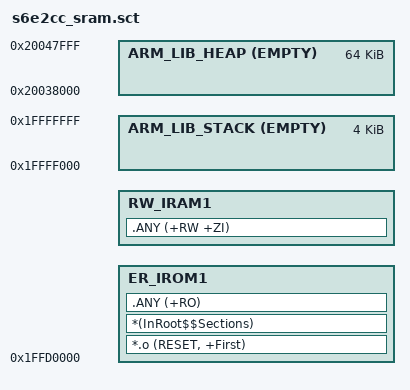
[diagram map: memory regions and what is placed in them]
;****************************************************************
;* S6E2CC linker scatter file (running code from internal SRAM) *
;****************************************************************

LR_IROM1 0x1FFD0000 0x30000
{
   ER_IROM1 0x1FFD0000
   {
      *.o (RESET, +First)
      *(InRoot$$Sections)
      .ANY (+RO)
   }
   
   RW_IRAM1 +0
   { 
      .ANY (+RW +ZI)
   }
   
   ScatterAssert((ImageLength(ER_IROM1) + ImageLength(RW_IRAM1)) < 0x2F000)
   
   ARM_LIB_STACK 0x20000000 EMPTY -0x1000
   {
   }
   
   ARM_LIB_HEAP 0x20038000 EMPTY 0x10000
   {
   }
}
